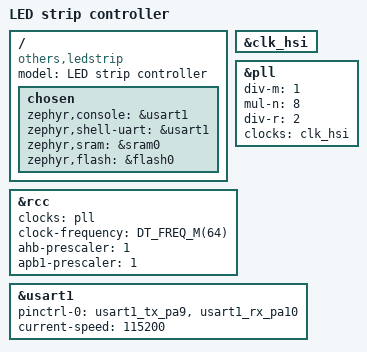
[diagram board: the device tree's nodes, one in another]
/dts-v1/;

#include <st/g0/stm32g030X6.dtsi>
#include <st/g0/stm32g030k(6-8)tx-pinctrl.dtsi>

/ {
	model = "LED strip controller";
	compatible = "others,ledstrip";

	chosen {
		zephyr,console = &usart1;
		zephyr,shell-uart = &usart1;
		zephyr,sram = &sram0;
		zephyr,flash = &flash0;
	};
};

&clk_hsi {
	status = "okay";
};

&pll {
	div-m = <1>;
	mul-n = <8>;
	div-r = <2>;
	clocks = <&clk_hsi>;
	status = "okay";
};

&rcc {
	clocks = <&pll>;
	clock-frequency = <DT_FREQ_M(64)>;
	ahb-prescaler = <1>;
	apb1-prescaler = <1>;
};

&usart1 {
	pinctrl-0 = <&usart1_tx_pa9 &usart1_rx_pa10>;
	pinctrl-names = "default";
	current-speed = <115200>;
	status = "okay";
};
